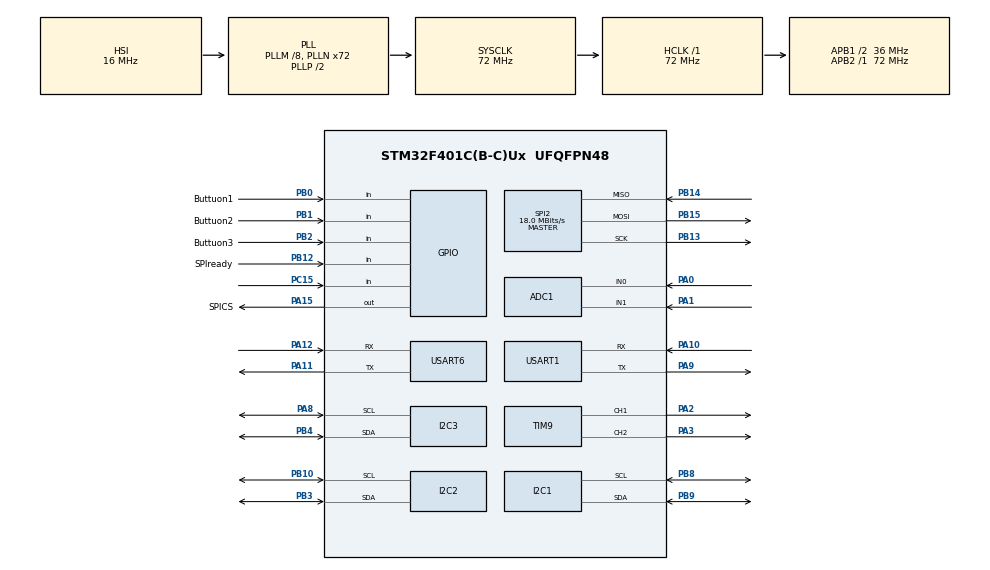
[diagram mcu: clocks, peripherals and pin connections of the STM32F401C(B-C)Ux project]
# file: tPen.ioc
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ADC1.Channel-0\#ChannelRegularConversion=ADC_CHANNEL_0
ADC1.Channel-1\#ChannelRegularConversion=ADC_CHANNEL_1
ADC1.ContinuousConvMode=ENABLE
ADC1.DMAContinuousRequests=ENABLE
ADC1.NbrOfConversion=2
ADC1.NbrOfConversionFlag=1
ADC1.Rank-0\#ChannelRegularConversion=1
ADC1.Rank-1\#ChannelRegularConversion=2
ADC1.SamplingTime-0\#ChannelRegularConversion=ADC_SAMPLETIME_480CYCLES
ADC1.SamplingTime-1\#ChannelRegularConversion=ADC_SAMPLETIME_480CYCLES
ADC1.master=1
Dma.ADC1.2.Direction=DMA_PERIPH_TO_MEMORY
Dma.ADC1.2.FIFOMode=DMA_FIFOMODE_DISABLE
Dma.ADC1.2.Instance=DMA2_Stream0
Dma.ADC1.2.MemDataAlignment=DMA_MDATAALIGN_HALFWORD
Dma.ADC1.2.MemInc=DMA_MINC_ENABLE
Dma.ADC1.2.Mode=DMA_CIRCULAR
Dma.ADC1.2.PeriphDataAlignment=DMA_PDATAALIGN_HALFWORD
Dma.ADC1.2.PeriphInc=DMA_PINC_DISABLE
Dma.ADC1.2.Priority=DMA_PRIORITY_LOW
Dma.Request0=USART1_RX
Dma.Request1=USART6_RX
Dma.Request2=ADC1
Dma.USART1_RX.0.Direction=DMA_PERIPH_TO_MEMORY
Dma.USART1_RX.0.FIFOMode=DMA_FIFOMODE_DISABLE
Dma.USART1_RX.0.Instance=DMA2_Stream2
Dma.USART1_RX.0.MemDataAlignment=DMA_MDATAALIGN_BYTE
Dma.USART1_RX.0.MemInc=DMA_MINC_ENABLE
Dma.USART1_RX.0.Mode=DMA_NORMAL
Dma.USART1_RX.0.PeriphDataAlignment=DMA_PDATAALIGN_BYTE
Dma.USART1_RX.0.PeriphInc=DMA_PINC_DISABLE
Dma.USART1_RX.0.Priority=DMA_PRIORITY_LOW
Dma.USART6_RX.1.Direction=DMA_PERIPH_TO_MEMORY
Dma.USART6_RX.1.FIFOMode=DMA_FIFOMODE_DISABLE
Dma.USART6_RX.1.Instance=DMA2_Stream1
Dma.USART6_RX.1.MemDataAlignment=DMA_MDATAALIGN_BYTE
Dma.USART6_RX.1.MemInc=DMA_MINC_ENABLE
Dma.USART6_RX.1.Mode=DMA_NORMAL
Dma.USART6_RX.1.PeriphDataAlignment=DMA_PDATAALIGN_BYTE
Dma.USART6_RX.1.PeriphInc=DMA_PINC_DISABLE
Dma.USART6_RX.1.Priority=DMA_PRIORITY_LOW
Mcu.Family=STM32F4
Mcu.Name=STM32F401C(B-C)Ux
Mcu.Package=UFQFPN48
NVIC.DMA2_Stream0_IRQn=true\:0\:0\:false\:false\:true\:false\:true\:true
NVIC.DMA2_Stream1_IRQn=true\:0\:0\:false\:false\:true\:false\:true\:true
NVIC.DMA2_Stream2_IRQn=true\:0\:0\:false\:false\:true\:false\:true\:true
NVIC.PriorityGroup=NVIC_PRIORITYGROUP_4
PA0-WKUP.Signal=ADCx_IN0
PA1.Signal=ADCx_IN1
PA10.Mode=Asynchronous
PA10.Signal=USART1_RX
PA11.Mode=Asynchronous
PA11.Signal=USART6_TX
PA12.Mode=Asynchronous
PA12.Signal=USART6_RX
PA13.Mode=Serial_Wire
PA13.Signal=SYS_JTMS-SWDIO
PA14.Mode=Serial_Wire
PA14.Signal=SYS_JTCK-SWCLK
PA15.GPIO_Label=SPICS
PA15.Signal=GPIO_Output
PA2.Signal=S_TIM9_CH1
PA3.Signal=S_TIM9_CH2
PA8.GPIO_Pu=GPIO_PULLUP
PA8.Mode=I2C
PA8.Signal=I2C3_SCL
PA9.Mode=Asynchronous
PA9.Signal=USART1_TX
PB0.GPIO_Label=Buttuon1
PB0.GPIO_PuPd=GPIO_PULLUP
PB0.Signal=GPIO_Input
PB1.GPIO_Label=Buttuon2
PB1.GPIO_PuPd=GPIO_PULLUP
PB1.Signal=GPIO_Input
PB10.GPIO_Pu=GPIO_PULLUP
PB10.Mode=I2C
PB10.Signal=I2C2_SCL
PB12.GPIO_Label=SPIready
PB12.Signal=GPIO_Input
PB13.Mode=Full_Duplex_Master
PB13.Signal=SPI2_SCK
PB14.Mode=Full_Duplex_Master
PB14.Signal=SPI2_MISO
PB15.Mode=Full_Duplex_Master
PB15.Signal=SPI2_MOSI
PB2.GPIO_Label=Buttuon3
PB2.GPIO_PuPd=GPIO_PULLUP
PB2.Signal=GPIO_Input
PB3.GPIO_Pu=GPIO_PULLUP
PB3.Mode=I2C
PB3.Signal=I2C2_SDA
PB4.GPIO_Pu=GPIO_PULLUP
PB4.Mode=I2C
PB4.Signal=I2C3_SDA
PB8.GPIO_Pu=GPIO_PULLUP
PB8.Mode=I2C
PB8.Signal=I2C1_SCL
PB9.GPIO_Pu=GPIO_PULLUP
PB9.Mode=I2C
PB9.Signal=I2C1_SDA
PC15-OSC32_OUT.Signal=GPIO_Input
ProjectManager.HeapSize=0x200
ProjectManager.StackSize=0x400
ProjectManager.TargetToolchain=EWARM V8.50
RCC.48MHZClocksFreq_Value=36000000
RCC.AHBFreq_Value=72000000
RCC.APB1CLKDivider=RCC_HCLK_DIV2
RCC.APB1Freq_Value=36000000
RCC.APB1TimFreq_Value=72000000
RCC.APB2Freq_Value=72000000
RCC.APB2TimFreq_Value=72000000
RCC.CortexFreq_Value=72000000
RCC.HCLKFreq_Value=72000000
RCC.HSE_VALUE=8000000
RCC.HSI_VALUE=16000000
RCC.LSE_VALUE=32768
RCC.PLLM=8
RCC.PLLN=72
RCC.SYSCLKFreq_VALUE=72000000
RCC.SYSCLKSource=RCC_SYSCLKSOURCE_PLLCLK
RCC.VCOOutputFreq_Value=144000000
SH.ADCx_IN0.0=ADC1_IN0,IN0
SH.ADCx_IN1.0=ADC1_IN1,IN1
SH.S_TIM9_CH1.0=TIM9_CH1,PWM Generation1 CH1
SH.S_TIM9_CH2.0=TIM9_CH2,PWM Generation2 CH2
SPI2.CalculateBaudRate=18.0 MBits/s
SPI2.Direction=SPI_DIRECTION_2LINES
SPI2.Mode=SPI_MODE_MASTER
SPI2.VirtualType=VM_MASTER
TIM9.Channel-PWM\ Generation1\ CH1=TIM_CHANNEL_1
TIM9.Channel-PWM\ Generation2\ CH2=TIM_CHANNEL_2
USART1.VirtualMode=VM_ASYNC
USART6.VirtualMode=VM_ASYNC
board=custom

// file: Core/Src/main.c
/* USER CODE BEGIN Header */
/**
  ******************************************************************************
  * @file           : main.c
  * @brief          : Main program body
  ******************************************************************************
  * @attention
  *
  * Copyright (c) 2022 STMicroelectronics.
  * All rights reserved.
  *
  * This software is licensed under terms that can be found in the LICENSE file
  * in the root directory of this software component.
  * If no LICENSE file comes with this software, it is provided AS-IS.
  *
  ******************************************************************************
  */
/* USER CODE END Header */
#include "main.h"

 ADC_HandleTypeDef hadc1;
DMA_HandleTypeDef hdma_adc1;

I2C_HandleTypeDef hi2c1;
I2C_HandleTypeDef hi2c2;
I2C_HandleTypeDef hi2c3;

SPI_HandleTypeDef hspi2;

TIM_HandleTypeDef htim9;

UART_HandleTypeDef huart1;
UART_HandleTypeDef huart6;
DMA_HandleTypeDef hdma_usart1_rx;
DMA_HandleTypeDef hdma_usart6_rx;

void SystemClock_Config(void);
static void MX_GPIO_Init(void);
static void MX_DMA_Init(void);
static void MX_I2C1_Init(void);
static void MX_USART1_UART_Init(void);
static void MX_USART6_UART_Init(void);
static void MX_ADC1_Init(void);
static void MX_I2C2_Init(void);
static void MX_I2C3_Init(void);
static void MX_SPI2_Init(void);
static void MX_TIM9_Init(void);

int main(void)
{

  /* MCU Configuration--------------------------------------------------------*/

  /* Reset of all peripherals, Initializes the Flash interface and the Systick. */
  HAL_Init();

  /* Configure the system clock */
  SystemClock_Config();

  /* Initialize all configured peripherals */
  MX_GPIO_Init();
  MX_DMA_Init();
  MX_I2C1_Init();
  MX_USART1_UART_Init();
  MX_USART6_UART_Init();
  MX_ADC1_Init();
  MX_I2C2_Init();
  MX_I2C3_Init();
  MX_SPI2_Init();
  MX_TIM9_Init();

  /* Infinite loop */
  while (1)
  {

    /* USER CODE BEGIN 3 */
     SuperRunSequence();
  }
  /* USER CODE END 3 */
}

void SystemClock_Config(void)
{
  RCC_OscInitTypeDef RCC_OscInitStruct = {0};
  RCC_ClkInitTypeDef RCC_ClkInitStruct = {0};

  /** Configure the main internal regulator output voltage
  */
  __HAL_RCC_PWR_CLK_ENABLE();
  __HAL_PWR_VOLTAGESCALING_CONFIG(PWR_REGULATOR_VOLTAGE_SCALE2);

  /** Initializes the RCC Oscillators according to the specified parameters
  * in the RCC_OscInitTypeDef structure.
  */
  RCC_OscInitStruct.OscillatorType = RCC_OSCILLATORTYPE_HSI;
  RCC_OscInitStruct.HSIState = RCC_HSI_ON;
  RCC_OscInitStruct.HSICalibrationValue = RCC_HSICALIBRATION_DEFAULT;
  RCC_OscInitStruct.PLL.PLLState = RCC_PLL_ON;
  RCC_OscInitStruct.PLL.PLLSource = RCC_PLLSOURCE_HSI;
  RCC_OscInitStruct.PLL.PLLM = 8;
  RCC_OscInitStruct.PLL.PLLN = 72;
  RCC_OscInitStruct.PLL.PLLP = RCC_PLLP_DIV2;
  RCC_OscInitStruct.PLL.PLLQ = 4;
  if (HAL_RCC_OscConfig(&RCC_OscInitStruct) != HAL_OK)
  {
    Error_Handler();
  }

  /** Initializes the CPU, AHB and APB buses clocks
  */
  RCC_ClkInitStruct.ClockType = RCC_CLOCKTYPE_HCLK|RCC_CLOCKTYPE_SYSCLK
                              |RCC_CLOCKTYPE_PCLK1|RCC_CLOCKTYPE_PCLK2;
  RCC_ClkInitStruct.SYSCLKSource = RCC_SYSCLKSOURCE_PLLCLK;
  RCC_ClkInitStruct.AHBCLKDivider = RCC_SYSCLK_DIV1;
  RCC_ClkInitStruct.APB1CLKDivider = RCC_HCLK_DIV2;
  RCC_ClkInitStruct.APB2CLKDivider = RCC_HCLK_DIV1;

  if (HAL_RCC_ClockConfig(&RCC_ClkInitStruct, FLASH_LATENCY_2) != HAL_OK)
  {
    Error_Handler();
  }
}

static void MX_ADC1_Init(void)
{

  ADC_ChannelConfTypeDef sConfig = {0};

  /** Configure the global features of the ADC (Clock, Resolution, Data Alignment and number of conversion)
  */
  hadc1.Instance = ADC1;
  hadc1.Init.ClockPrescaler = ADC_CLOCK_SYNC_PCLK_DIV2;
  hadc1.Init.Resolution = ADC_RESOLUTION_12B;
  hadc1.Init.ScanConvMode = ENABLE;
  hadc1.Init.ContinuousConvMode = ENABLE;
  hadc1.Init.DiscontinuousConvMode = DISABLE;
  hadc1.Init.ExternalTrigConvEdge = ADC_EXTERNALTRIGCONVEDGE_NONE;
  hadc1.Init.ExternalTrigConv = ADC_SOFTWARE_START;
  hadc1.Init.DataAlign = ADC_DATAALIGN_RIGHT;
  hadc1.Init.NbrOfConversion = 2;
  hadc1.Init.DMAContinuousRequests = ENABLE;
  hadc1.Init.EOCSelection = ADC_EOC_SINGLE_CONV;
  if (HAL_ADC_Init(&hadc1) != HAL_OK)
  {
    Error_Handler();
  }

  /** Configure for the selected ADC regular channel its corresponding rank in the sequencer and its sample time.
  */
  sConfig.Channel = ADC_CHANNEL_0;
  sConfig.Rank = 1;
  sConfig.SamplingTime = ADC_SAMPLETIME_480CYCLES;
  if (HAL_ADC_ConfigChannel(&hadc1, &sConfig) != HAL_OK)
  {
    Error_Handler();
  }

  /** Configure for the selected ADC regular channel its corresponding rank in the sequencer and its sample time.
  */
  sConfig.Channel = ADC_CHANNEL_1;
  sConfig.Rank = 2;
  if (HAL_ADC_ConfigChannel(&hadc1, &sConfig) != HAL_OK)
  {
    Error_Handler();
  }

}

static void MX_I2C1_Init(void)
{

  hi2c1.Instance = I2C1;
  hi2c1.Init.ClockSpeed = 100000;
  hi2c1.Init.DutyCycle = I2C_DUTYCYCLE_2;
  hi2c1.Init.OwnAddress1 = 0;
  hi2c1.Init.AddressingMode = I2C_ADDRESSINGMODE_7BIT;
  hi2c1.Init.DualAddressMode = I2C_DUALADDRESS_DISABLE;
  hi2c1.Init.OwnAddress2 = 0;
  hi2c1.Init.GeneralCallMode = I2C_GENERALCALL_DISABLE;
  hi2c1.Init.NoStretchMode = I2C_NOSTRETCH_DISABLE;
  if (HAL_I2C_Init(&hi2c1) != HAL_OK)
  {
    Error_Handler();
  }

}

static void MX_I2C2_Init(void)
{

  hi2c2.Instance = I2C2;
  hi2c2.Init.ClockSpeed = 100000;
  hi2c2.Init.DutyCycle = I2C_DUTYCYCLE_2;
  hi2c2.Init.OwnAddress1 = 0;
  hi2c2.Init.AddressingMode = I2C_ADDRESSINGMODE_7BIT;
  hi2c2.Init.DualAddressMode = I2C_DUALADDRESS_DISABLE;
  hi2c2.Init.OwnAddress2 = 0;
  hi2c2.Init.GeneralCallMode = I2C_GENERALCALL_DISABLE;
  hi2c2.Init.NoStretchMode = I2C_NOSTRETCH_DISABLE;
  if (HAL_I2C_Init(&hi2c2) != HAL_OK)
  {
    Error_Handler();
  }

}

static void MX_I2C3_Init(void)
{

  hi2c3.Instance = I2C3;
  hi2c3.Init.ClockSpeed = 100000;
  hi2c3.Init.DutyCycle = I2C_DUTYCYCLE_2;
  hi2c3.Init.OwnAddress1 = 0;
  hi2c3.Init.AddressingMode = I2C_ADDRESSINGMODE_7BIT;
  hi2c3.Init.DualAddressMode = I2C_DUALADDRESS_DISABLE;
  hi2c3.Init.OwnAddress2 = 0;
  hi2c3.Init.GeneralCallMode = I2C_GENERALCALL_DISABLE;
  hi2c3.Init.NoStretchMode = I2C_NOSTRETCH_DISABLE;
  if (HAL_I2C_Init(&hi2c3) != HAL_OK)
  {
    Error_Handler();
  }

}

static void MX_SPI2_Init(void)
{

  /* SPI2 parameter configuration*/
  hspi2.Instance = SPI2;
  hspi2.Init.Mode = SPI_MODE_MASTER;
  hspi2.Init.Direction = SPI_DIRECTION_2LINES;
  hspi2.Init.DataSize = SPI_DATASIZE_8BIT;
  hspi2.Init.CLKPolarity = SPI_POLARITY_LOW;
  hspi2.Init.CLKPhase = SPI_PHASE_1EDGE;
  hspi2.Init.NSS = SPI_NSS_SOFT;
  hspi2.Init.BaudRatePrescaler = SPI_BAUDRATEPRESCALER_2;
  hspi2.Init.FirstBit = SPI_FIRSTBIT_MSB;
  hspi2.Init.TIMode = SPI_TIMODE_DISABLE;
  hspi2.Init.CRCCalculation = SPI_CRCCALCULATION_DISABLE;
  hspi2.Init.CRCPolynomial = 10;
  if (HAL_SPI_Init(&hspi2) != HAL_OK)
  {
    Error_Handler();
  }

}

static void MX_TIM9_Init(void)
{

  TIM_OC_InitTypeDef sConfigOC = {0};

  htim9.Instance = TIM9;
  htim9.Init.Prescaler = 0;
  htim9.Init.CounterMode = TIM_COUNTERMODE_UP;
  htim9.Init.Period = 65535;
  htim9.Init.ClockDivision = TIM_CLOCKDIVISION_DIV1;
  htim9.Init.AutoReloadPreload = TIM_AUTORELOAD_PRELOAD_DISABLE;
  if (HAL_TIM_PWM_Init(&htim9) != HAL_OK)
  {
    Error_Handler();
  }
  sConfigOC.OCMode = TIM_OCMODE_PWM1;
  sConfigOC.Pulse = 0;
  sConfigOC.OCPolarity = TIM_OCPOLARITY_HIGH;
  sConfigOC.OCFastMode = TIM_OCFAST_DISABLE;
  if (HAL_TIM_PWM_ConfigChannel(&htim9, &sConfigOC, TIM_CHANNEL_1) != HAL_OK)
  {
    Error_Handler();
  }
  if (HAL_TIM_PWM_ConfigChannel(&htim9, &sConfigOC, TIM_CHANNEL_2) != HAL_OK)
  {
    Error_Handler();
  }
  HAL_TIM_MspPostInit(&htim9);

}

static void MX_USART1_UART_Init(void)
{

  huart1.Instance = USART1;
  huart1.Init.BaudRate = 115200;
  huart1.Init.WordLength = UART_WORDLENGTH_8B;
  huart1.Init.StopBits = UART_STOPBITS_1;
  huart1.Init.Parity = UART_PARITY_NONE;
  huart1.Init.Mode = UART_MODE_TX_RX;
  huart1.Init.HwFlowCtl = UART_HWCONTROL_NONE;
  huart1.Init.OverSampling = UART_OVERSAMPLING_16;
  if (HAL_UART_Init(&huart1) != HAL_OK)
  {
    Error_Handler();
  }

}

static void MX_USART6_UART_Init(void)
{

  huart6.Instance = USART6;
  huart6.Init.BaudRate = 115200;
  huart6.Init.WordLength = UART_WORDLENGTH_8B;
  huart6.Init.StopBits = UART_STOPBITS_1;
  huart6.Init.Parity = UART_PARITY_NONE;
  huart6.Init.Mode = UART_MODE_TX_RX;
  huart6.Init.HwFlowCtl = UART_HWCONTROL_NONE;
  huart6.Init.OverSampling = UART_OVERSAMPLING_16;
  if (HAL_UART_Init(&huart6) != HAL_OK)
  {
    Error_Handler();
  }

}

static void MX_DMA_Init(void)
{

  /* DMA controller clock enable */
  __HAL_RCC_DMA2_CLK_ENABLE();

  /* DMA interrupt init */
  /* DMA2_Stream0_IRQn interrupt configuration */
  HAL_NVIC_SetPriority(DMA2_Stream0_IRQn, 0, 0);
  HAL_NVIC_EnableIRQ(DMA2_Stream0_IRQn);
  /* DMA2_Stream1_IRQn interrupt configuration */
  HAL_NVIC_SetPriority(DMA2_Stream1_IRQn, 0, 0);
  HAL_NVIC_EnableIRQ(DMA2_Stream1_IRQn);
  /* DMA2_Stream2_IRQn interrupt configuration */
  HAL_NVIC_SetPriority(DMA2_Stream2_IRQn, 0, 0);
  HAL_NVIC_EnableIRQ(DMA2_Stream2_IRQn);

}

static void MX_GPIO_Init(void)
{
  GPIO_InitTypeDef GPIO_InitStruct = {0};

  /* GPIO Ports Clock Enable */
  __HAL_RCC_GPIOC_CLK_ENABLE();
  __HAL_RCC_GPIOA_CLK_ENABLE();
  __HAL_RCC_GPIOB_CLK_ENABLE();

  /*Configure GPIO pin Output Level */
  HAL_GPIO_WritePin(SPICS_GPIO_Port, SPICS_Pin, GPIO_PIN_RESET);

  /*Configure GPIO pin : PC15 */
  GPIO_InitStruct.Pin = GPIO_PIN_15;
  GPIO_InitStruct.Mode = GPIO_MODE_INPUT;
  GPIO_InitStruct.Pull = GPIO_NOPULL;
  HAL_GPIO_Init(GPIOC, &GPIO_InitStruct);

  /*Configure GPIO pins : Buttuon1_Pin Buttuon2_Pin Buttuon3_Pin */
  GPIO_InitStruct.Pin = Buttuon1_Pin|Buttuon2_Pin|Buttuon3_Pin;
  GPIO_InitStruct.Mode = GPIO_MODE_INPUT;
  GPIO_InitStruct.Pull = GPIO_PULLUP;
  HAL_GPIO_Init(GPIOB, &GPIO_InitStruct);

  /*Configure GPIO pin : SPIready_Pin */
  GPIO_InitStruct.Pin = SPIready_Pin;
  GPIO_InitStruct.Mode = GPIO_MODE_INPUT;
  GPIO_InitStruct.Pull = GPIO_NOPULL;
  HAL_GPIO_Init(SPIready_GPIO_Port, &GPIO_InitStruct);

  /*Configure GPIO pin : SPICS_Pin */
  GPIO_InitStruct.Pin = SPICS_Pin;
  GPIO_InitStruct.Mode = GPIO_MODE_OUTPUT_PP;
  GPIO_InitStruct.Pull = GPIO_NOPULL;
  GPIO_InitStruct.Speed = GPIO_SPEED_FREQ_LOW;
  HAL_GPIO_Init(SPICS_GPIO_Port, &GPIO_InitStruct);

}

void Error_Handler(void)
{
  __disable_irq();
  while (1)
  {
  }
}
